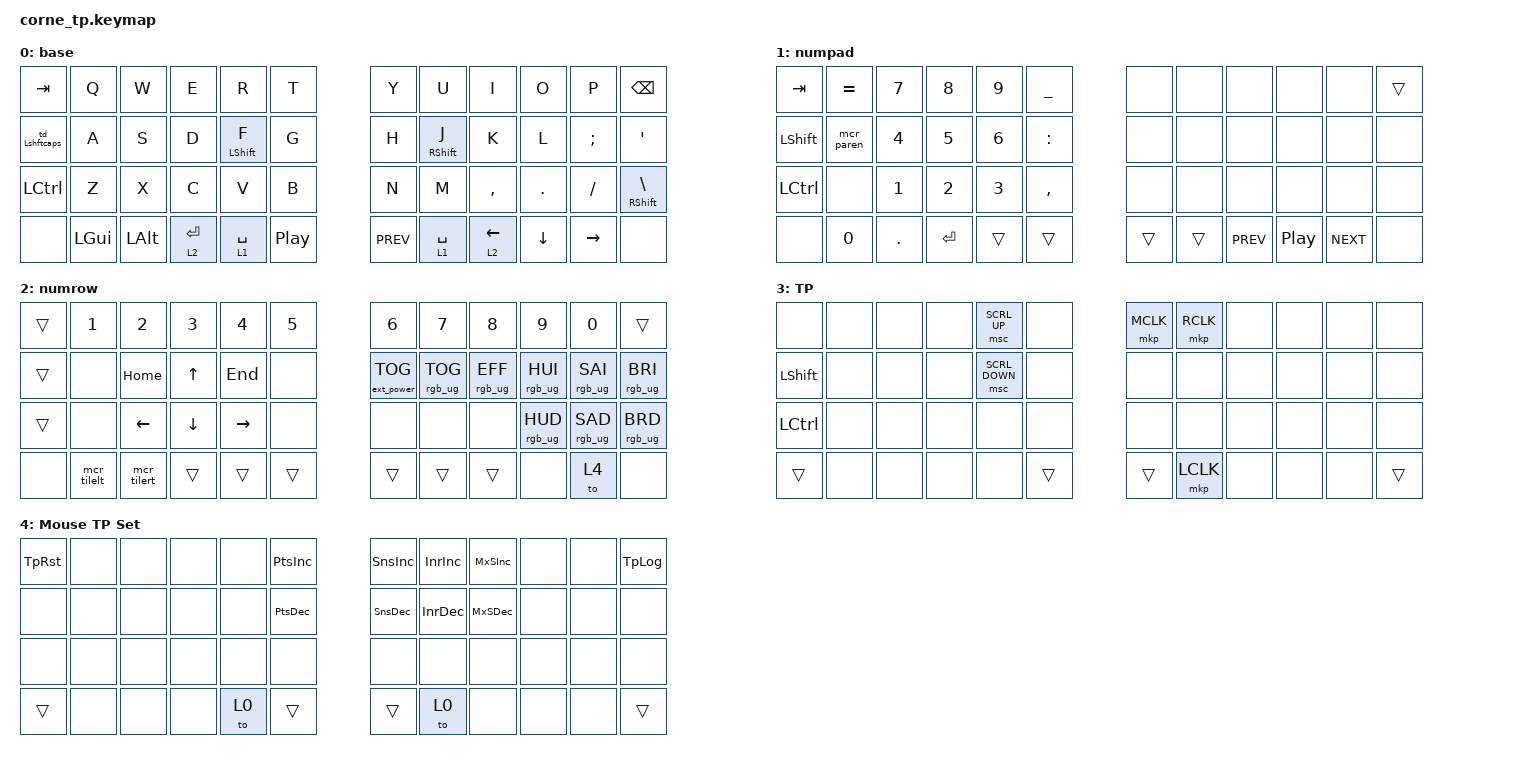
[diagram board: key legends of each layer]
#include <behaviors.dtsi>
#include <dt-bindings/zmk/keys.h>
#include <dt-bindings/zmk/bt.h>
#include <dt-bindings/zmk/ext_power.h>
#include <dt-bindings/zmk/rgb.h>

#define base 0
#define numpad 1
#define numrow_layer 2
#define TP_layer 3
#define MouseSettings_layer 4

#define KEYS_LEFT       0 1 2 3 4 5 12 13 14 15 16 17 24 25 26 27 28 29
#define KEYS_LEFT_NO_F  0 1 2 3 4 5 12 13 14 15    17 24 25 26 27 28 29
#define KEYS_RIGHT      6 7 8 9 10 11 18 19 20 21 22 23 30 31 32 33 34 35
#define KEYS_RIGHT_NO_J 6 7 8 9 10 11 18    20 21 22 23 30 31 32 33 34 35

// This defines a special way of defining combos that makes them way more compact
#define COMBO(NAME, BINDINGS, KEYPOS) \
  combo_##NAME { \
    timeout-ms = <30>; \
    bindings = <BINDINGS>; \
    key-positions = <KEYPOS>; \
    layers = <0 1 2 3 4>; \
  };
#define STRINGIFY(x) #x
#define EXPAND_AND_STRINGIFY(x) STRINGIFY(x)
#define MACRO(NAME, BINDINGS) \
  mcr_##NAME: mcr_##NAME { \
    label = EXPAND_AND_STRINGIFY(mcr_##NAME); \
    compatible = "zmk,behavior-macro"; \
    #binding-cells = <0>; \
    wait-ms = <20>; \
    tap-ms = <10>; \
    bindings = <BINDINGS>; \
  };

/*
 * Defines to enable/disable features
 *
 * These defines allow us to conditionally enable and disable parts of the keymap config.
 * For example, if we decide to build the firmware without the mouse features, we can
 * disable all the config options that rely on those forks and modules without having
 * to edit the entire keymap file manually every time.
 */

#define HAS_MOUSE_KEYS
#define HAS_MOUSE_TP

#ifdef HAS_MOUSE_KEYS
  #include <dt-bindings/zmk/mouse.h>
  #include <behaviors/mouse_keys.dtsi>
#endif

// Store the trackpoint settings in a separate file to make organization easier
#ifdef HAS_MOUSE_TP
  #include "include/mouse_tp.dtsi"
#endif

// Adjust layer keys based on enabled features. This prevents build errors when we
// build the firmware without the mouse keys PR or the TP module.
#ifdef HAS_MOUSE_KEYS
  #define U_THUMB_INNER &mo MOUSE_KEYS
#else
  #define U_THUMB_INNER &none
#endif

&mt {
    tapping-term-ms = <200>;
    retro-tap;
};

/ {
    macros {
        // Symbol macros and others
        MACRO(deg, &macro_press &kp LALT &macro_tap &kp KP_N2 &kp KP_N4 &kp KP_N8 &macro_release &kp LALT)   // degree
        MACRO(mu, &macro_press &kp LALT &macro_tap &kp KP_N2 &kp KP_N3 &kp KP_N0 &macro_release &kp LALT)    // mu
        MACRO(eps, &macro_press &kp LALT &macro_tap &kp KP_N2 &kp KP_N3 &kp KP_N8 &macro_release &kp LALT)   // epsilon
        MACRO(pi, &macro_press &kp LALT &macro_tap &kp KP_N2 &kp KP_N2 &kp KP_N7 &macro_release &kp LALT)    // pi
        MACRO(sig, &macro_press &kp LALT &macro_tap &kp KP_N2 &kp KP_N2 &kp KP_N9 &macro_release &kp LSHFT &kp LALT)   // sigma
        MACRO(delta, &macro_press &kp LSHFT &kp LALT &macro_tap &kp D &macro_release &kp LSHFT &kp LALT)     // Δ
        MACRO(plsmns, &macro_press &kp LALT &macro_tap &kp KP_N0 &kp KP_N1 &kp KP_N7 &kp KP_N7 &macro_release &kp LALT)   // plus minus symbol
        MACRO(int, &macro_press &kp LSHFT &macro_tap &kp I &macro_release &kp LSHFT &macro_tap &kp N &kp T &kp E &kp R &kp F &kp E &kp R &kp O &kp M &kp E &kp T &kp E &kp R &kp N2 &kp RET)
        MACRO(paren, &macro_tap &kp F2 &kp LPAR &kp RPAR &kp LEFT)   // double parenthesis
        MACRO(in, &macro_tap &kp I &kp N)     // inches
        MACRO(mm, &macro_tap &kp M &kp M)     // millimeters
        MACRO(altb, &macro_press &kp LALT &macro_tap &kp TAB &macro_release &kp LALT)   // alt+tab
        MACRO(tilelt, &macro_press &kp LGUI &macro_tap &kp LEFT &macro_release &kp LGUI)   // tile left
        MACRO(tilert, &macro_press &kp LGUI &macro_tap &kp RIGHT &macro_release &kp LGUI)   // tile right

        // Macros to move by whole words and select words
        MACRO(PWrd, &macro_press &kp LCTRL &macro_tap &kp LEFT &macro_release &kp LCTRL)
        //MACRO(NWrd, &macro_press &kp LCTRL &macro_tap &kp RIGHT &macro_release &kp LCTRL)
        //MACRO(sel_prv, &macro_press &kp LCTRL &kp LSHFT &macro_tap &kp LEFT &macro_release &kp LCTRL &kp LSHFT)
        //MACRO(sel_wrd, &macro_press &kp LCTRL &macro_tap &kp RIGHT &macro_press &kp LSHFT &macro_tap &kp LEFT &macro_release &kp LCTRL &kp LSHFT)
        //MACRO(sel_nxt, &macro_press &kp LCTRL &kp LSHFT &macro_tap &kp RIGHT &macro_release &kp LCTRL &kp LSHFT)

        // Macros to type common decimal numbers in SolidWorks
        MACRO(025, &macro_press &kp LCTRL &macro_tap &kp A &macro_release &kp LCTRL &macro_tap &kp KP_N0 &kp DOT &kp KP_N0 &kp KP_N2 &kp KP_N5)
        MACRO(100, &macro_press &kp LCTRL &macro_tap &kp A &macro_release &kp LCTRL &macro_tap &kp KP_N0 &kp DOT &kp KP_N1)
        MACRO(125, &macro_press &kp LCTRL &macro_tap &kp A &macro_release &kp LCTRL &macro_tap &kp KP_N0 &kp DOT &kp KP_N1 &kp KP_N2 &kp KP_N5)
        MACRO(187, &macro_press &kp LCTRL &macro_tap &kp A &macro_release &kp LCTRL &macro_tap &kp KP_N0 &kp DOT &kp KP_N1 &kp KP_N8 &kp KP_N7 &kp KP_N5)
        MACRO(250, &macro_press &kp LCTRL &macro_tap &kp A &macro_release &kp LCTRL &macro_tap &kp KP_N0 &kp DOT &kp KP_N2 &kp KP_N5)
        MACRO(375, &macro_press &kp LCTRL &macro_tap &kp A &macro_release &kp LCTRL &macro_tap &kp KP_N0 &kp DOT &kp KP_N3 &kp KP_N7 &kp KP_N5)
        MACRO(500, &macro_press &kp LCTRL &macro_tap &kp A &macro_release &kp LCTRL &macro_tap &kp KP_N0 &kp DOT &kp KP_N5)
        MACRO(625, &macro_press &kp LCTRL &macro_tap &kp A &macro_release &kp LCTRL &macro_tap &kp KP_N0 &kp DOT &kp KP_N6 &kp KP_N2 &kp KP_N5)
        MACRO(750, &macro_press &kp LCTRL &macro_tap &kp A &macro_release &kp LCTRL &macro_tap &kp KP_N0 &kp DOT &kp KP_N7 &kp KP_N5)
        MACRO(875, &macro_press &kp LCTRL &macro_tap &kp A &macro_release &kp LCTRL &macro_tap &kp KP_N0 &kp DOT &kp KP_N8 &kp KP_N7 &kp KP_N5)
};

//                         KEY POSITIONS
// ╭────────────────────────────╮ ╭────────────────────────────╮
// │  0   1   2   3   4   5     │ │     6   7   8   9   10  11 │
// │ 12  13  14  15  16  17     │ │     18  19  20  21  22  23 │
// │ 24  25  26  27  28  29 (41)| │(42) 30  31  32  33  34  35 │
// ╰───────╮(36) 37  38  39  40 │ │ 43  44  45  46  (47)╭──────╯
//         ╰────────────────────╯ ╰─────────────────────╯

  combos {
    compatible = "zmk,combos";

// ╭─────────────────────────╮   COMBOS with   ╭────────────────────────╮
// │ _   _    (   )   =   _  │ SPACE  (40, 43) │ {Δ} {µ} {ε}  _   _   _ │
// │ _   _    [   ]   +   -  ╰───╮        ╭────╯  _   _   _   _   _   _ │
// │ _   °    {   }   *   /   ◯ │        │ ◯    _   _   _   _   _   _ │
// ╰───────╮ ◯  PRSC _   _   ●  │        │  ●    _   _   _   ◯ ╭──────╯
//         ╰─────────────────────╯        ╰──────────────────────╯
            COMBO(cmb_pscrn, &kp PSCRN, 37 40)

            COMBO(cmb_lpar, &kp LPAR, 2 40)      // parathesis and others
            COMBO(cmb_rpar, &kp RPAR, 3 40)
            COMBO(cmb_lbrack, &kp LBKT, 14 40)
            COMBO(cmb_rbrack, &kp RBKT, 15 40)
            COMBO(cmb_lbrace, &kp LBRC, 26 40)
            COMBO(cmb_rbrace, &kp RBRC, 27 40)

            COMBO(cmb_equal, &kp EQUAL, 4 40)  // math symbols
            COMBO(cmb_under, &kp UNDER, 5 40)
            COMBO(cmb_plus1, &kp PLUS, 16 40)
            COMBO(cmb_minus1, &kp MINUS, 17 40)
            COMBO(cmb_times1, &kp STAR, 28 40)
            COMBO(cmb_divide1, &kp SLASH, 29 40)

            // other symbols
            COMBO(deg, &mcr_deg, 25 40)            // degree
            COMBO(delta, &mcr_delta, 6 43)         // delta
            COMBO(mu, &mcr_mu, 7 43)               // mu
            COMBO(eps, &mcr_eps, 8 43)             // epsilon

// ╭─────────────────────────────╮   COMBOS with   ╭───────────────────────╮
// │ ~   !    @    #    $     %  │ RAISE  (39, 44) │ ^   &   *   (   )   ` │
// │ _ .375 .500 .625 .750  .875 ╰────╮       ╭────╯ _   _   _   [   ]   _ │
// │ _ .025 .100 .125 .1875 .250  (_) │       │ (_)  _   _   _   {   }   _ │
// ╰──────╮  (_)   _    _     ●    _  │       │  _   ●   _   _  (_) ╭──────╯
//        ╰───────────────────────────╯       ╰─────────────────────╯
            COMBO(cmb_tilde, &kp TILDE, 0 39)  // left hand
            COMBO(cmb_shft1, &kp EXCL, 1 39)
            COMBO(cmb_shft2, &kp AT, 2 39)
            COMBO(cmb_shft3, &kp HASH, 3 39)
            COMBO(cmb_shft4, &kp DLLR, 4 39)
            COMBO(cmb_shft5, &kp PRCNT, 5 39)
            COMBO(cmb_shft6, &kp CARET, 6 44)  // right hand
            COMBO(cmb_shft7, &kp AMPS, 7 44)
            COMBO(cmb_shft8, &kp STAR, 8 44)
            COMBO(cmb_shft9, &kp LPAR, 9 44)
            COMBO(cmb_shft0, &kp RPAR, 10 44)
            COMBO(cmb_grave, &kp GRAVE, 11 44)

// ╭───────────────────────────╮  OTHER    ╭──────────────────────────╮
// │ _{esc}_{bs}_{dl}_   _   _ │  COMBOS   │ _    _   _   _   _     _ │
// │ _     _    _ {-}_{+}_   _ ╰────╮ ╭────╯ _    _   _   _   _{ret}_ │
// │ _     _    _ {*}_{/}_{±}_   ◯ | | ◯   _    _   _   _   _     _ │
// ╰────────╮  ◯    _   _   _   _  │ │  _   _{up}_   _   ◯ ╭────────╯
//          ╰───────────────────────╯ ╰──────────────────────╯
            COMBO(bspc, &kp BSPC, 1 2)
            COMBO(del, &kp DEL, 2 3)
            COMBO(esc, &kp ESC, 0 1)
            COMBO(enter, &kp RET, 22 23)
            COMBO(plsmns, &mcr_plsmns, 28 29)
            COMBO(up, &kp UP, 44 45)          // up arrow by pressing left and down
            COMBO(int, &mcr_int, 9 10 11)
            COMBO(mouse, &to 4, 30 35)        // go to mouse settings layer
            COMBO(home1, &kp HOME, 30 44)     // home
            COMBO(end1, &kp END, 31 44)       // end
            COMBO(home2, &kp HOME, 28 39)     // home
            COMBO(end2, &kp END, 29 39)       // end
            COMBO(minus, &kp MINUS, 14 15)    // minus
            COMBO(plus, &kp PLUS, 15 16)      // plus
            COMBO(star, &kp STAR, 26 27)    // minus
            COMBO(slash, &kp SLASH, 27 28)      // plus
  };
};

/ {
    behaviors {
      // tapdance behavior: used to turn on caps lock by double tapping left shift
      td_Lshftcaps: td_Lshftcaps {
        compatible = "zmk,behavior-tap-dance";
        label = "td_Lshftcaps";
        #binding-cells = <0>;
        tapping-term-ms = <200>;
        bindings = <&kp LSHFT>, <&kp CAPS>;
      };
      hml: home_row_mod_left {
            compatible = "zmk,behavior-hold-tap";
            #binding-cells = <2>;
            flavor = "balanced";
            require-prior-idle-ms = <150>;
            tapping-term-ms = <280>;
            quick-tap-ms = <175>;
            bindings = <&kp>, <&kp>;
            hold-trigger-key-positions = <KEYS_RIGHT>; // keys on the right side that can be paired with the left side mod
            hold-trigger-on-release;
        };
        hmr: home_row_mod_right {
            compatible = "zmk,behavior-hold-tap";
            #binding-cells = <2>;
            flavor = "balanced";
            require-prior-idle-ms = <150>;
            tapping-term-ms = <280>;
            quick-tap-ms = <175>;
            bindings = <&kp>, <&kp>;
            hold-trigger-key-positions = <KEYS_LEFT>;
            hold-trigger-on-release;
        };
    };
   
  keymap {
    compatible = "zmk,keymap";

    base_layer {
      display-name = "base";
      bindings = <
      // ╭────────────────────────────────╮                ╭─────────────────────────────────╮
      // |  TAB     Q    W    E    R   T  |                |  Y    U    I    O    P    BSPC  |
      // | SHFT/CAP A    S    D    F   G  ╰───────╮ ╭──────╯  H    J    K    L    ;:   ' "   |
      // |  CTRL    Z    X    C    V   B    (PP)  | | (prev)  N    M    ,    .    /?  \|SHFT |
      // ╰──────────╮   ◯   GUI  ALT ENTER SPACE | | SPACE  SHFT  <-   ->   ◯  ╭───────────╯
      //            ╰────────────────  nav numpad ╯ ╰ numpad nav ────────────────╯

        &kp TAB   &kp Q     &kp W    &kp E      &kp R       &kp T                &kp Y       &kp U     &kp I     &kp O     &kp P     &kp BSPC
    &td_Lshftcaps &kp A     &kp S    &kp D   &hml LSHFT F   &kp G                &kp H    &hmr RSHFT J &kp K     &kp L     &kp SEMI  &kp SQT
        &kp LCTRL &kp Z     &kp X    &kp C      &kp V       &kp B                &kp N       &kp M     &kp COMMA &kp DOT   &kp SLASH &mt RSHFT BSLH
        &none     &kp LGUI  &kp LALT &lt 2 RET &lt 1 SPACE &kp C_PP   &kp C_PREV &lt 1 SPACE &lt 2 LEFT &kp DOWN  &kp RIGHT &none
      >;
      sensor-bindings = <
        &inc_dec_kp LEFT RIGHT
        &inc_dec_kp C_VOL_DN C_VOL_UP
        >;
    };

    numpad_layer {
      display-name = "numpad";
      bindings = <
      // ╭───────────────────────────╮          ╭──────────────────────────────╮
      // | TAB   =    7   8   9   _  |          |                         BSPC |
      // | SHFT  ()   4   5   6   :  ╰────╮ ╭───╯                              |
      // | CTRL       1   2   3   ,    ◯ | | ◯                               |
      // ╰────────╮  ◯   0   .  ENT   ●  | |  ● PrvTrk _ NxtTrk ◯ ╭──────────╯
      //          ╰───────────────────────╯ ╰───────────────────────╯

        &kp TAB   &kp EQUAL  &kp N7  &kp N8  &kp N9 &kp UNDER                 &none &none &none &none &none &trans
        &kp LSHFT &mcr_paren &kp N4  &kp N5  &kp N6 &kp COLON                 &none &none &none &none &none &none
        &kp LCTRL &none      &kp N1  &kp N2  &kp N3 &kp COMMA                 &none &none &none &none &none &none
                  &none      &kp N0    &kp DOT &kp RET &trans &trans   &trans &trans &kp C_PREV &kp C_PP &kp C_NEXT &none
      >;
      sensor-bindings = <
        &inc_dec_kp LEFT RIGHT
        &inc_dec_kp C_VOL_DN C_VOL_UP
        >;
    };

    numrow_layer {
      display-name = "numrow";
      bindings = <
      // ╭─────────────────────────────╮          ╭──────────────────────────────╮
      // | TAB  1    2    3    4    5  |          |  6    7    8    9    0  BSPC |
      // | SHFT     HOME  ^   END      ╰───╮ ╭────╯ Pwr  RGB  Eff  hue+ sat+ br+ |
      // | CTRL      <-   v   ->        ◯ | | ◯                  hue- sat- br- |
      // ╰────────╮ ◯    TL   TR  ● SPACE | | SPACE ●       TPSet  ◯ ╭─────────╯
      //          ╰────────────────────────╯ ╰─────────────────────────╯

        &trans &kp N1 &kp N2   &kp N3   &kp N4    &kp N5             &kp N6   &kp N7   &kp N8    &kp N9   &kp N0   &trans
        &trans &none  &kp HOME &kp UP   &kp END   &none              &ext_power EP_TOG &rgb_ug RGB_TOG &rgb_ug RGB_EFF &rgb_ug RGB_HUI &rgb_ug RGB_SAI &rgb_ug RGB_BRI
        &trans &none  &kp LEFT &kp DOWN &kp RIGHT &none              &none &none &none &rgb_ug RGB_HUD &rgb_ug RGB_SAD  &rgb_ug RGB_BRD
        &none &mcr_tilelt &mcr_tilert &trans &trans &trans    &trans &trans &trans &none &to 4 &none
      >;
      // encoder order: RH Left, RH Right, LH Left, LH Right
      sensor-bindings = <
        &inc_dec_kp LEFT RIGHT
        &inc_dec_kp C_VOL_DN C_VOL_UP
        >;
    };

    // Automatically activated when the mouse or trackpoint moves
    // Configured in `include/mouse_tp.dtsi`
    TP_layer {
      display-name = "TP";
      bindings = <
        // ╭─────────────────────────╮           ╭───────────────────────────╮
        // |  -    -   -   -  ScU  - |           | MClk RClk  -   -   -   -  |
        // | Shft  -   -   -  ScD  - ╰────╮ ╭────╯  -    -    -   -   -   -  |
        // | Ctrl  -   -   -   -   -  ( ) | | ( )   -    -    -   -   -   -  |
        // ╰───────╮  ( )  -   -   -   -  | | LClk  -    -    -  ( ) ╭───────╯
        //         ╰──────────────────────╯ ╰────────────────────────╯
            &none &none &none &none &msc SCRL_UP   &none       &mkp MCLK &mkp RCLK &none &none &none &none
        &kp LSHFT &none &none &none &msc SCRL_DOWN &none       &none     &none     &none &none &none &none
        &kp LCTRL &none &none &none &none          &none       &none     &none     &none &none &none &none
           &trans &none &none &none &none          &trans     &trans     &mkp LCLK &none &none &none &trans
      >;
      // encoder order: RH Left, RH Right, LH Left, LH Right
      sensor-bindings = <
        &inc_dec_kp LEFT RIGHT
        &inc_dec_kp C_VOL_DN C_VOL_UP
        >;
    };

    // Defininitions for these behaviors are in include/mouse_tp.dtsi
    MouseSettings_layer {
      display-name = "Mouse TP Set";
      bindings = <
        // ╭────────────────────────────╮           ╭───────────────────────────╮
        // | Reset  -   -   -   -  Pts+ |           | Sns+ Inr+ MxS+ -   -  Log |
        // |   -    -   -   -   -  Pts- ╰────╮ ╭────╯ Sns- Inr- MxS- -   -   -  |
        // |   -    -   -   -   -   -    ( ) | | ( )   -    -    -   -   -   -  |
        // ╰────────╮  ( )  -   -   -   to 0 | | to 0  -    -    -  ( ) ╭───────╯     !!!!! return to base layer upon pressing space !!!!!
        //          ╰────────────────────────╯ ╰────────────────────────╯
        TpRst  &none &none &none &none PtsInc     SnsInc InrInc MxSInc &none &none TpLog
        &none  &none &none &none &none PtsDec     SnsDec InrDec MxSDec &none &none &none
        &none  &none &none &none &none &none      &none  &none  &none  &none &none &none
        &trans &none &none &none &to 0 &trans     &trans &to 0  &none  &none &none &trans
      >;
      // encoder order: RH Left, RH Right, LH Left, LH Right
      sensor-bindings = <
        &inc_dec_kp LEFT RIGHT
        &inc_dec_kp C_VOL_DN C_VOL_UP
        >;
    };
  };
};


        // ╭──────────────────────────╮           ╭─────────────────────────╮
        // |   -    -   -   -   -   - |           | -   -   -   -   -   -   |
        // |   -    -   -   -   -   - ╰────╮ ╭────╯ -   -   -   -   -   -   |
        // |   -    -   -   -   -   -  ( ) | | ( )  -   -   -   -   -   -   |
        // ╰────────╮  ( )  -   -   -   -  | |  -   -   -   -  ( ) ╭────────╯
        //          ╰──────────────────────╯ ╰─────────────────────╯
